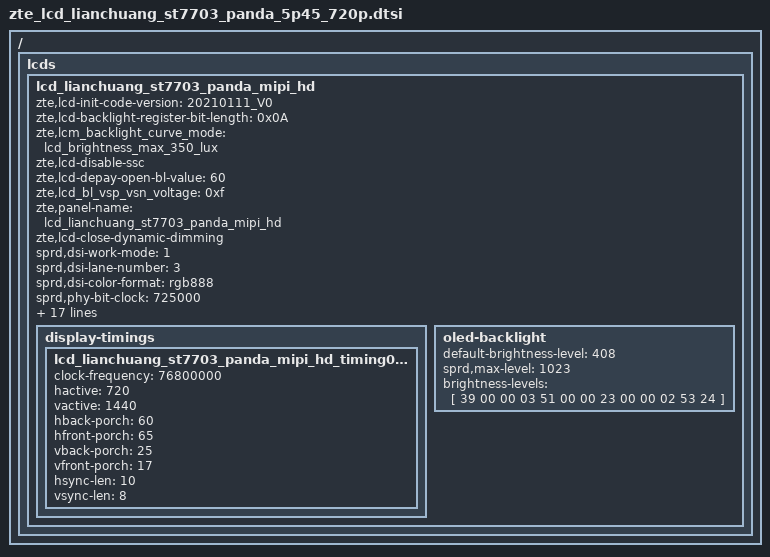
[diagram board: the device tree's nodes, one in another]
/ { lcds {
	lcd_lianchuang_st7703_panda_mipi_hd: lcd_lianchuang_st7703_panda_mipi_hd {
		zte,lcd-init-code-version = "20210111_V0";
		zte,lcd-backlight-register-bit-length = <0x0A>;
		zte,lcm_backlight_curve_mode = "lcd_brightness_max_350_lux";
		zte,lcd-disable-ssc;
		zte,lcd-depay-open-bl-value = <60>;
		zte,lcd_bl_vsp_vsn_voltage = <0xf>;
		zte,panel-name = "lcd_lianchuang_st7703_panda_mipi_hd";
		zte,lcd-close-dynamic-dimming;

		sprd,dsi-work-mode = <1>; /* video burst mode*/
		sprd,dsi-lane-number = <3>;
		sprd,dsi-color-format = "rgb888";

		sprd,phy-bit-clock = <725000>;	/* kbps */
		sprd,phy-escape-clock = <20000>;/* kHz */

		sprd,width-mm = <61884>;
		sprd,height-mm = <123768>;

		sprd,esd-check-enable = <1>;/* 0:close , 1:open */
		sprd,esd-check-mode = <1>;/* 0:REG ,1:TE  */
		sprd,esd-check-period = <1000>;
		sprd,esd-check-register = <0x0A>;
		sprd,esd-check-value = <0x9C>;
		zte,lcd-reset-pin-before-vsp;
		sprd,reset-on-sequence = <1 10>, <0 12>, <1 20>;
		sprd,reset-off-sequence = <0 0>, <0 0>, <0 20>;
		sprd,initial-command = [
			39 00 00 04 B9 F1 12 83
			39 00 00 06 B1 85 04 20 DB 81
			39 00 00 04 B2 F0 12 D0
			39 00 00 0B B3 10 10 28 28 03 FF 00 00 00 00
			23 00 00 02 B4 00
			39 00 00 03 B5 09 09
			39 00 00 03 B6 1E 1E
			23 00 00 02 B8 75
			39 00 00 1C BA 32 81 05 F9 0E 0E 20 00 00
						00 00 00 00 00 44 25 00 91 0A
						00 00 01 4F C1 7F 7A 37
			23 00 00 02 BC 4F
			39 00 00 04 BF 02 11 00
			39 00 00 0A C0 73 73 50 50 00 00 12 70 00
			39 00 00 0D C1 25 00 32 32 BB E1 FF FF AF AF 7F 7F
			39 00 00 07 C6 81 00 FF FF 00 7F
			39 00 00 05 CA 00 01 0F 0F
			23 00 00 02 CC 0B
			39 00 00 23 E0 00 23 27 26 38 3F 54 3F 08
						0D 0E 13 15 13 14 10 16 00 23
						27 26 38 3F 54 3F 08 0D 0E 13
						15 13 14 10 16
			39 00 00 0F E3 03 03 03 03 00 03 00 00 00
						00 FF 80 00 10
			39 00 00 40 E9 C8 10 0A 05 A5 80 81 12 31
						23 6F 88 80 2D 47 0A 00 00 C2
						00 00 00 00 00 C2 00 00 00 85
						88 F8 51 18 87 58 83 88 88 88
						84 88 F8 40 08 86 48 82 88 88
						88 00 00 00 01 00 00 00 00 00
						00 00 00 00
			39 00 00 40 EA 00 1A 00 00 00 00 02 00 00
						00 00 00 84 88 8F 04 28 84 68
						80 88 88 88 85 88 8F 15 38 85
						78 81 88 88 88 23 00 00 00 E8
						00 00 00 00 00 00 00 00 00 00
						00 10 0F 50 00 40 80 2D C0 00
						00 00 30 00
			39 00 00 04 EF FF FF 01
			23 00 00 07 C7 B8 00 0A 00 00 02
			39 00 00 04 C8 00 00 04
			39 00 00 03 51 00 00
			23 00 00 02 53 2C
			23 00 00 02 55 00
			23 00 00 02 5E 04
			23 78 00 02 11 00
			23 32 00 02 29 00
			];
		sprd,sleep-in-command = [
			39 00 00 03 51 00 00
			13 50 00 01 28
			13 F0 00 01 10
			];
		sprd,sleep-out-command = [
			13 78 00 01 11
			13 14 00 01 29
			];

		display-timings {
			lcd_lianchuang_st7703_panda_mipi_hd_timing0: timing0 {
			clock-frequency = <76800000>;
			hactive = <720>;
			vactive = <1440>;
			hback-porch = <60>;
			hfront-porch = <65>;
			vback-porch = <25>;
			vfront-porch = <17>;
			hsync-len = <10>;
			vsync-len = <8>;
			};
		};
		oled-backlight {
			default-brightness-level = <408>;
			sprd,max-level = <1023>;
			brightness-levels = [
				39 00 00 03 51 00 00
				23 00 00 02 53 24
			];
		};
	};
};};

